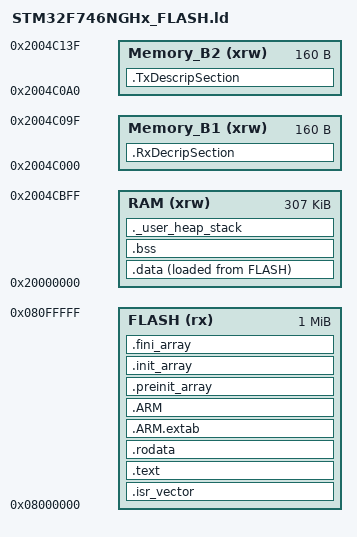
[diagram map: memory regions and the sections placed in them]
/*
*****************************************************************************
**

**  File        : LinkerScript.ld
**
**  Abstract    : Linker script for STM32F746NGHx Device with
**                1024KByte FLASH, 320KByte RAM
**
**                Set heap size, stack size and stack location according
**                to application requirements.
**
**                Set memory bank area and size if external memory is used.
**
**  Target      : STMicroelectronics STM32
**
**
**  Distribution: The file is distributed as is, without any warranty
**                of any kind.
**
*****************************************************************************
**
**  File provided by SW4STM32
**
*****************************************************************************
*/

/* Entry Point */
ENTRY(Reset_Handler)

/* Highest address of the user mode stack */
_estack = 0x20050000;    /* end of RAM */
/* Generate a link error if heap and stack don't fit into RAM */
_Min_Heap_Size = 0x200;      /* required amount of heap  */
_Min_Stack_Size = 0x460; /* required amount of stack */

/* Specify the memory areas */
MEMORY
{
FLASH (rx)       : ORIGIN = 0x08000000, LENGTH = 1024K
RAM (xrw)        : ORIGIN = 0x20000000, LENGTH = 307K
Memory_B1(xrw)   : ORIGIN = 0x2004C000, LENGTH = 0xA0
Memory_B2(xrw)   : ORIGIN = 0x2004C0A0, LENGTH = 0xA0
}

PHDRS
{
  text PT_LOAD FLAGS(5);
  data PT_LOAD FLAGS(6);
}

/* Define output sections */
SECTIONS
{
  /* The startup code goes first into FLASH */
  .isr_vector :
  {
    . = ALIGN(4);
    KEEP(*(.isr_vector)) /* Startup code */
    . = ALIGN(4);
  } >FLASH :text

  /* The program code and other data goes into FLASH */
  .text :
  {
    . = ALIGN(4);
    *(.text)           /* .text sections (code) */
    *(.text*)          /* .text* sections (code) */
    *(.glue_7)         /* glue arm to thumb code */
    *(.glue_7t)        /* glue thumb to arm code */
    *(.eh_frame)

    KEEP (*(.init))
    KEEP (*(.fini))

    . = ALIGN(4);
    _etext = .;        /* define a global symbols at end of code */
  } >FLASH :text

  /* Constant data goes into FLASH */
  .rodata :
  {
    . = ALIGN(4);
    *(.rodata)         /* .rodata sections (constants, strings, etc.) */
    *(.rodata*)        /* .rodata* sections (constants, strings, etc.) */
    . = ALIGN(4);
  } >FLASH :text

  .ARM.extab   : { *(.ARM.extab* .gnu.linkonce.armextab.*) } >FLASH :text
  .ARM : {
    __exidx_start = .;
    *(.ARM.exidx*)
    __exidx_end = .;
  } >FLASH :text

  .preinit_array     :
  {
    PROVIDE_HIDDEN (__preinit_array_start = .);
    KEEP (*(.preinit_array*))
    PROVIDE_HIDDEN (__preinit_array_end = .);
  } >FLASH :text
  .init_array :
  {
    PROVIDE_HIDDEN (__init_array_start = .);
    KEEP (*(SORT(.init_array.*)))
    KEEP (*(.init_array*))
    PROVIDE_HIDDEN (__init_array_end = .);
  } >FLASH :text
  .fini_array :
  {
    PROVIDE_HIDDEN (__fini_array_start = .);
    KEEP (*(SORT(.fini_array.*)))
    KEEP (*(.fini_array*))
    PROVIDE_HIDDEN (__fini_array_end = .);
  } >FLASH :text

  /* used by the startup to initialize data */
  _sidata = LOADADDR(.data);

  /* Initialized data sections goes into RAM, load LMA copy after code */
  .data : 
  {
    . = ALIGN(4);
    _sdata = .;        /* create a global symbol at data start */
    *(.data)           /* .data sections */
    *(.data*)          /* .data* sections */

    . = ALIGN(4);
    _edata = .;        /* define a global symbol at data end */
  } >RAM AT> FLASH :data

  
  /* Uninitialized data section */
  . = ALIGN(4);
  .bss (NOLOAD) :
  {
    /* This is used by the startup in order to initialize the .bss section */
    _sbss = .;         /* define a global symbol at bss start */
    __bss_start__ = _sbss;
    *(.bss)
    *(.bss*)
    *(COMMON)

    . = ALIGN(4);
    _ebss = .;         /* define a global symbol at bss end */
    __bss_end__ = _ebss;
  } >RAM :NONE

  /* User_heap_stack section, used to check that there is enough RAM left */
  ._user_heap_stack (NOLOAD) :
  {
    . = ALIGN(8);
    PROVIDE ( end = . );
    PROVIDE ( _end = . );
    . = . + _Min_Heap_Size;
    . = . + _Min_Stack_Size;
    . = ALIGN(8);
  } >RAM :NONE

  

  /* Remove information from the standard libraries */
  /DISCARD/ :
  {
    libc.a ( * )
    libm.a ( * )
    libgcc.a ( * )
  }

   .ARM.attributes 0 : { *(.ARM.attributes) } :NONE
  .RxDecripSection (NOLOAD) : { *(.RxDescripSection) } >Memory_B1 :NONE
  .TxDescripSection (NOLOAD) : { *(.TxDescripSection) } >Memory_B2 :NONE
}

